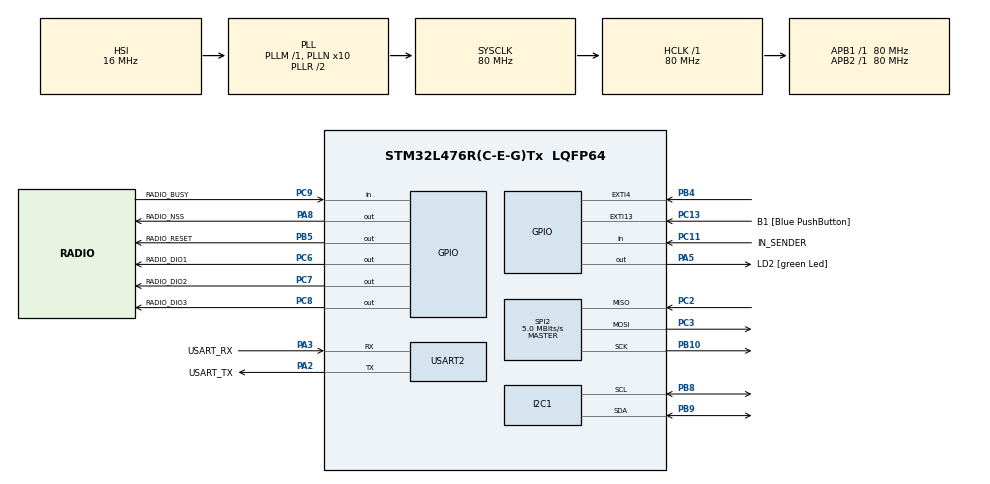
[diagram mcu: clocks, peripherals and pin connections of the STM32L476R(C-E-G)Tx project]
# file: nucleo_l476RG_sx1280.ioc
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I2C1.Timing=0x10D19CE4
Mcu.Family=STM32L4
Mcu.Name=STM32L476R(C-E-G)Tx
Mcu.Package=LQFP64
NVIC.EXTI15_10_IRQn=true\:0\:0\:false\:false\:true\:true\:true\:true
NVIC.EXTI4_IRQn=true\:0\:0\:false\:false\:true\:true\:true\:true
NVIC.PriorityGroup=NVIC_PRIORITYGROUP_4
NVIC.USART2_IRQn=true\:0\:0\:false\:false\:true\:true\:true\:true
PA13\ (JTMS-SWDIO).GPIO_Label=TMS
PA13\ (JTMS-SWDIO).Mode=Serial_Wire
PA13\ (JTMS-SWDIO).Signal=SYS_JTMS-SWDIO
PA14\ (JTCK-SWCLK).GPIO_Label=TCK
PA14\ (JTCK-SWCLK).Mode=Serial_Wire
PA14\ (JTCK-SWCLK).Signal=SYS_JTCK-SWCLK
PA2.GPIO_Label=USART_TX
PA2.GPIO_Mode=GPIO_MODE_AF_PP
PA2.GPIO_PuPd=GPIO_NOPULL
PA2.GPIO_Speed=GPIO_SPEED_FREQ_VERY_HIGH
PA2.Mode=Asynchronous
PA2.Signal=USART2_TX
PA3.GPIO_Label=USART_RX
PA3.GPIO_Mode=GPIO_MODE_AF_PP
PA3.GPIO_PuPd=GPIO_NOPULL
PA3.GPIO_Speed=GPIO_SPEED_FREQ_VERY_HIGH
PA3.Mode=Asynchronous
PA3.Signal=USART2_RX
PA5.GPIO_Label=LD2 [green Led]
PA5.GPIO_ModeDefaultOutputPP=GPIO_MODE_OUTPUT_PP
PA5.GPIO_PuPd=GPIO_NOPULL
PA5.GPIO_Speed=GPIO_SPEED_FREQ_LOW
PA5.Signal=GPIO_Output
PA8.GPIO_Label=RADIO_NSS
PA8.Signal=GPIO_Output
PB10.Mode=Full_Duplex_Master
PB10.Signal=SPI2_SCK
PB3\ (JTDO-TRACESWO).GPIO_Label=SWO
PB3\ (JTDO-TRACESWO).Signal=SYS_JTDO-SWO
PB4\ (NJTRST).Signal=GPXTI4
PB5.GPIO_Label=RADIO_RESET
PB5.Signal=GPIO_Output
PB8.Mode=I2C
PB8.Signal=I2C1_SCL
PB9.Mode=I2C
PB9.Signal=I2C1_SDA
PC11.GPIO_Label=IN_SENDER
PC11.GPIO_PuPd=GPIO_PULLDOWN
PC11.Signal=GPIO_Input
PC13.GPIO_Label=B1 [Blue PushButton]
PC13.GPIO_ModeDefaultEXTI=GPIO_MODE_IT_FALLING
PC13.GPIO_PuPd=GPIO_NOPULL
PC13.Signal=GPXTI13
PC14-OSC32_IN\ (PC14).Mode=LSE-External-Oscillator
PC14-OSC32_IN\ (PC14).Signal=RCC_OSC32_IN
PC15-OSC32_OUT\ (PC15).Mode=LSE-External-Oscillator
PC15-OSC32_OUT\ (PC15).Signal=RCC_OSC32_OUT
PC2.Mode=Full_Duplex_Master
PC2.Signal=SPI2_MISO
PC3.Mode=Full_Duplex_Master
PC3.Signal=SPI2_MOSI
PC6.GPIO_Label=RADIO_DIO1
PC6.Signal=GPIO_Output
PC7.GPIO_Label=RADIO_DIO2
PC7.Signal=GPIO_Output
PC8.GPIO_Label=RADIO_DIO3
PC8.Signal=GPIO_Output
PC9.GPIO_Label=RADIO_BUSY
PC9.Signal=GPIO_Input
PH0-OSC_IN\ (PH0).Signal=RCC_OSC_IN
PH1-OSC_OUT\ (PH1).Signal=RCC_OSC_OUT
ProjectManager.HeapSize=0x200
ProjectManager.StackSize=0x400
ProjectManager.TargetToolchain=CMake
RCC.ADCFreq_Value=64000000
RCC.AHBFreq_Value=80000000
RCC.APB1Freq_Value=80000000
RCC.APB1TimFreq_Value=80000000
RCC.APB2Freq_Value=80000000
RCC.APB2TimFreq_Value=80000000
RCC.CortexFreq_Value=80000000
RCC.HCLKFreq_Value=80000000
RCC.HSE_VALUE=8000000
RCC.HSI_VALUE=16000000
RCC.MSI_VALUE=4000000
RCC.PLLN=10
RCC.PLLSourceVirtual=RCC_PLLSOURCE_HSI
RCC.PREFETCH_ENABLE=1
RCC.SYSCLKFreq_VALUE=80000000
RCC.SYSCLKSource=RCC_SYSCLKSOURCE_PLLCLK
RCC.USBFreq_Value=64000000
RCC.VCOOutputFreq_Value=160000000
SPI2.BaudRatePrescaler=SPI_BAUDRATEPRESCALER_16
SPI2.CalculateBaudRate=5.0 MBits/s
SPI2.DataSize=SPI_DATASIZE_8BIT
SPI2.Direction=SPI_DIRECTION_2LINES
SPI2.Mode=SPI_MODE_MASTER
SPI2.NSSPMode=SPI_NSS_PULSE_DISABLE
SPI2.VirtualType=VM_MASTER
USART2.VirtualMode-Asynchronous=VM_ASYNC
VP_LPTIM1_VS_LPTIM_counterModeInternalClock.Mode=Counts__internal_clock_event_00
VP_RTC_VS_RTC_Activate.Mode=RTC_Enabled
board=NUCLEO-L476RG

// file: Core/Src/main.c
/* USER CODE BEGIN Header */
/**
  ******************************************************************************
  * @file           : main.c
  * @brief          : Main program body
  ******************************************************************************
  * @attention
  *
  * Copyright (c) 2026 STMicroelectronics.
  * All rights reserved.
  *
  * This software is licensed under terms that can be found in the LICENSE file
  * in the root directory of this software component.
  * If no LICENSE file comes with this software, it is provided AS-IS.
  *
  ******************************************************************************
  */
/* USER CODE END Header */
#include "main.h"

/* USER CODE BEGIN Includes */
#include "stdio.h"
#include "stdlib.h"
#include "stdbool.h"
#include "stm32l4xx_hal.h"
#include "stm32l4xx_hal_gpio.h"

/* USER CODE END Includes */

I2C_HandleTypeDef hi2c1;

LPTIM_HandleTypeDef hlptim1;

RTC_HandleTypeDef hrtc;

SPI_HandleTypeDef hspi2;

UART_HandleTypeDef huart2;

/* USER CODE BEGIN PV */

#ifdef __GNUC__
int __io_putchar(int ch)
#else
int fputc(int ch, FILE *f)
#endif
{
    HAL_UART_Transmit(&huart2, (uint8_t *)&ch, 1, HAL_MAX_DELAY);
    return ch;
}

/* USER CODE END PV */

void SystemClock_Config(void);
static void MX_GPIO_Init(void);
static void MX_USART2_UART_Init(void);
static void MX_I2C1_Init(void);
static void MX_SPI2_Init(void);
static void MX_LPTIM1_Init(void);
static void MX_RTC_Init(void);

int main(void)
{

  /* MCU Configuration--------------------------------------------------------*/

  /* Reset of all peripherals, Initializes the Flash interface and the Systick. */
  HAL_Init();

  /* Configure the system clock */
  SystemClock_Config();

  /* Initialize all configured peripherals */
  MX_GPIO_Init();
  MX_USART2_UART_Init();
  MX_I2C1_Init();
  MX_SPI2_Init();
  MX_LPTIM1_Init();
  MX_RTC_Init();

  /* Infinite loop */
  /* USER CODE BEGIN WHILE */
  printf("DARIO: start pingpong task\r\n");
  // pingpong_main();
  dario_main();

  while (1)
  {
    /* USER CODE END WHILE */

  }
}

void SystemClock_Config(void)
{
  RCC_OscInitTypeDef RCC_OscInitStruct = {0};
  RCC_ClkInitTypeDef RCC_ClkInitStruct = {0};

  /** Configure the main internal regulator output voltage
  */
  if (HAL_PWREx_ControlVoltageScaling(PWR_REGULATOR_VOLTAGE_SCALE1) != HAL_OK)
  {
    Error_Handler();
  }

  /** Initializes the RCC Oscillators according to the specified parameters
  * in the RCC_OscInitTypeDef structure.
  */
  RCC_OscInitStruct.OscillatorType = RCC_OSCILLATORTYPE_HSI|RCC_OSCILLATORTYPE_LSI;
  RCC_OscInitStruct.HSIState = RCC_HSI_ON;
  RCC_OscInitStruct.HSICalibrationValue = RCC_HSICALIBRATION_DEFAULT;
  RCC_OscInitStruct.LSIState = RCC_LSI_ON;
  RCC_OscInitStruct.PLL.PLLState = RCC_PLL_ON;
  RCC_OscInitStruct.PLL.PLLSource = RCC_PLLSOURCE_HSI;
  RCC_OscInitStruct.PLL.PLLM = 1;
  RCC_OscInitStruct.PLL.PLLN = 10;
  RCC_OscInitStruct.PLL.PLLP = RCC_PLLP_DIV7;
  RCC_OscInitStruct.PLL.PLLQ = RCC_PLLQ_DIV2;
  RCC_OscInitStruct.PLL.PLLR = RCC_PLLR_DIV2;
  if (HAL_RCC_OscConfig(&RCC_OscInitStruct) != HAL_OK)
  {
    Error_Handler();
  }

  /** Initializes the CPU, AHB and APB buses clocks
  */
  RCC_ClkInitStruct.ClockType = RCC_CLOCKTYPE_HCLK|RCC_CLOCKTYPE_SYSCLK
                              |RCC_CLOCKTYPE_PCLK1|RCC_CLOCKTYPE_PCLK2;
  RCC_ClkInitStruct.SYSCLKSource = RCC_SYSCLKSOURCE_PLLCLK;
  RCC_ClkInitStruct.AHBCLKDivider = RCC_SYSCLK_DIV1;
  RCC_ClkInitStruct.APB1CLKDivider = RCC_HCLK_DIV1;
  RCC_ClkInitStruct.APB2CLKDivider = RCC_HCLK_DIV1;

  if (HAL_RCC_ClockConfig(&RCC_ClkInitStruct, FLASH_LATENCY_4) != HAL_OK)
  {
    Error_Handler();
  }
}

static void MX_I2C1_Init(void)
{

  hi2c1.Instance = I2C1;
  hi2c1.Init.Timing = 0x10D19CE4;
  hi2c1.Init.OwnAddress1 = 0;
  hi2c1.Init.AddressingMode = I2C_ADDRESSINGMODE_7BIT;
  hi2c1.Init.DualAddressMode = I2C_DUALADDRESS_DISABLE;
  hi2c1.Init.OwnAddress2 = 0;
  hi2c1.Init.OwnAddress2Masks = I2C_OA2_NOMASK;
  hi2c1.Init.GeneralCallMode = I2C_GENERALCALL_DISABLE;
  hi2c1.Init.NoStretchMode = I2C_NOSTRETCH_DISABLE;
  if (HAL_I2C_Init(&hi2c1) != HAL_OK)
  {
    Error_Handler();
  }

  /** Configure Analogue filter
  */
  if (HAL_I2CEx_ConfigAnalogFilter(&hi2c1, I2C_ANALOGFILTER_ENABLE) != HAL_OK)
  {
    Error_Handler();
  }

  /** Configure Digital filter
  */
  if (HAL_I2CEx_ConfigDigitalFilter(&hi2c1, 0) != HAL_OK)
  {
    Error_Handler();
  }

}

static void MX_LPTIM1_Init(void)
{

  hlptim1.Instance = LPTIM1;
  hlptim1.Init.Clock.Source = LPTIM_CLOCKSOURCE_APBCLOCK_LPOSC;
  hlptim1.Init.Clock.Prescaler = LPTIM_PRESCALER_DIV1;
  hlptim1.Init.Trigger.Source = LPTIM_TRIGSOURCE_SOFTWARE;
  hlptim1.Init.OutputPolarity = LPTIM_OUTPUTPOLARITY_HIGH;
  hlptim1.Init.UpdateMode = LPTIM_UPDATE_IMMEDIATE;
  hlptim1.Init.CounterSource = LPTIM_COUNTERSOURCE_INTERNAL;
  hlptim1.Init.Input1Source = LPTIM_INPUT1SOURCE_GPIO;
  hlptim1.Init.Input2Source = LPTIM_INPUT2SOURCE_GPIO;
  if (HAL_LPTIM_Init(&hlptim1) != HAL_OK)
  {
    Error_Handler();
  }

}

static void MX_RTC_Init(void)
{

  /** Initialize RTC Only
  */
  hrtc.Instance = RTC;
  hrtc.Init.HourFormat = RTC_HOURFORMAT_24;
  hrtc.Init.AsynchPrediv = 127;
  hrtc.Init.SynchPrediv = 255;
  hrtc.Init.OutPut = RTC_OUTPUT_DISABLE;
  hrtc.Init.OutPutRemap = RTC_OUTPUT_REMAP_NONE;
  hrtc.Init.OutPutPolarity = RTC_OUTPUT_POLARITY_HIGH;
  hrtc.Init.OutPutType = RTC_OUTPUT_TYPE_OPENDRAIN;
  if (HAL_RTC_Init(&hrtc) != HAL_OK)
  {
    Error_Handler();
  }

}

static void MX_SPI2_Init(void)
{

  /* SPI2 parameter configuration*/
  hspi2.Instance = SPI2;
  hspi2.Init.Mode = SPI_MODE_MASTER;
  hspi2.Init.Direction = SPI_DIRECTION_2LINES;
  hspi2.Init.DataSize = SPI_DATASIZE_8BIT;
  hspi2.Init.CLKPolarity = SPI_POLARITY_LOW;
  hspi2.Init.CLKPhase = SPI_PHASE_1EDGE;
  hspi2.Init.NSS = SPI_NSS_SOFT;
  hspi2.Init.BaudRatePrescaler = SPI_BAUDRATEPRESCALER_16;
  hspi2.Init.FirstBit = SPI_FIRSTBIT_MSB;
  hspi2.Init.TIMode = SPI_TIMODE_DISABLE;
  hspi2.Init.CRCCalculation = SPI_CRCCALCULATION_DISABLE;
  hspi2.Init.CRCPolynomial = 7;
  hspi2.Init.CRCLength = SPI_CRC_LENGTH_DATASIZE;
  hspi2.Init.NSSPMode = SPI_NSS_PULSE_DISABLE;
  if (HAL_SPI_Init(&hspi2) != HAL_OK)
  {
    Error_Handler();
  }
  /* USER CODE BEGIN SPI2_Init 2 */

  // SPI_HandleTypeDef RadioSpiHandle;
  // RadioSpiHandle = hspi2;

  /* USER CODE END SPI2_Init 2 */

}

static void MX_USART2_UART_Init(void)
{

  huart2.Instance = USART2;
  huart2.Init.BaudRate = 115200;
  huart2.Init.WordLength = UART_WORDLENGTH_8B;
  huart2.Init.StopBits = UART_STOPBITS_1;
  huart2.Init.Parity = UART_PARITY_NONE;
  huart2.Init.Mode = UART_MODE_TX_RX;
  huart2.Init.HwFlowCtl = UART_HWCONTROL_NONE;
  huart2.Init.OverSampling = UART_OVERSAMPLING_16;
  huart2.Init.OneBitSampling = UART_ONE_BIT_SAMPLE_DISABLE;
  huart2.AdvancedInit.AdvFeatureInit = UART_ADVFEATURE_NO_INIT;
  if (HAL_UART_Init(&huart2) != HAL_OK)
  {
    Error_Handler();
  }

}

static void MX_GPIO_Init(void)
{
  GPIO_InitTypeDef GPIO_InitStruct = {0};

  /* GPIO Ports Clock Enable */
  __HAL_RCC_GPIOC_CLK_ENABLE();
  __HAL_RCC_GPIOH_CLK_ENABLE();
  __HAL_RCC_GPIOA_CLK_ENABLE();
  __HAL_RCC_GPIOB_CLK_ENABLE();

  /*Configure GPIO pin Output Level */
  HAL_GPIO_WritePin(GPIOA, LD2_Pin|RADIO_NSS_Pin, GPIO_PIN_RESET);

  /*Configure GPIO pin Output Level */
  HAL_GPIO_WritePin(GPIOC, RADIO_DIO1_Pin|RADIO_DIO2_Pin|RADIO_DIO3_Pin, GPIO_PIN_RESET);

  /*Configure GPIO pin Output Level */
  HAL_GPIO_WritePin(RADIO_RESET_GPIO_Port, RADIO_RESET_Pin, GPIO_PIN_RESET);

  /*Configure GPIO pin : B1_Pin */
  GPIO_InitStruct.Pin = B1_Pin;
  GPIO_InitStruct.Mode = GPIO_MODE_IT_FALLING;
  GPIO_InitStruct.Pull = GPIO_NOPULL;
  HAL_GPIO_Init(B1_GPIO_Port, &GPIO_InitStruct);

  /*Configure GPIO pins : LD2_Pin RADIO_NSS_Pin */
  GPIO_InitStruct.Pin = LD2_Pin|RADIO_NSS_Pin;
  GPIO_InitStruct.Mode = GPIO_MODE_OUTPUT_PP;
  GPIO_InitStruct.Pull = GPIO_NOPULL;
  GPIO_InitStruct.Speed = GPIO_SPEED_FREQ_LOW;
  HAL_GPIO_Init(GPIOA, &GPIO_InitStruct);

  /*Configure GPIO pins : RADIO_DIO1_Pin RADIO_DIO2_Pin RADIO_DIO3_Pin */
  GPIO_InitStruct.Pin = RADIO_DIO1_Pin|RADIO_DIO2_Pin|RADIO_DIO3_Pin;
  GPIO_InitStruct.Mode = GPIO_MODE_OUTPUT_PP;
  GPIO_InitStruct.Pull = GPIO_NOPULL;
  GPIO_InitStruct.Speed = GPIO_SPEED_FREQ_LOW;
  HAL_GPIO_Init(GPIOC, &GPIO_InitStruct);

  /*Configure GPIO pin : RADIO_BUSY_Pin */
  GPIO_InitStruct.Pin = RADIO_BUSY_Pin;
  GPIO_InitStruct.Mode = GPIO_MODE_INPUT;
  GPIO_InitStruct.Pull = GPIO_NOPULL;
  HAL_GPIO_Init(RADIO_BUSY_GPIO_Port, &GPIO_InitStruct);

  /*Configure GPIO pin : IN_SENDER_Pin */
  GPIO_InitStruct.Pin = IN_SENDER_Pin;
  GPIO_InitStruct.Mode = GPIO_MODE_INPUT;
  GPIO_InitStruct.Pull = GPIO_PULLDOWN;
  HAL_GPIO_Init(IN_SENDER_GPIO_Port, &GPIO_InitStruct);

  /*Configure GPIO pin : PB4 */
  GPIO_InitStruct.Pin = GPIO_PIN_4;
  GPIO_InitStruct.Mode = GPIO_MODE_IT_RISING;
  GPIO_InitStruct.Pull = GPIO_NOPULL;
  HAL_GPIO_Init(GPIOB, &GPIO_InitStruct);

  /*Configure GPIO pin : RADIO_RESET_Pin */
  GPIO_InitStruct.Pin = RADIO_RESET_Pin;
  GPIO_InitStruct.Mode = GPIO_MODE_OUTPUT_PP;
  GPIO_InitStruct.Pull = GPIO_NOPULL;
  GPIO_InitStruct.Speed = GPIO_SPEED_FREQ_LOW;
  HAL_GPIO_Init(RADIO_RESET_GPIO_Port, &GPIO_InitStruct);

  /* EXTI interrupt init*/
  HAL_NVIC_SetPriority(EXTI4_IRQn, 0, 0);
  HAL_NVIC_EnableIRQ(EXTI4_IRQn);

  HAL_NVIC_SetPriority(EXTI15_10_IRQn, 0, 0);
  HAL_NVIC_EnableIRQ(EXTI15_10_IRQn);

}

void Error_Handler(void)
{
  __disable_irq();
  while (1)
  {
  }
}
